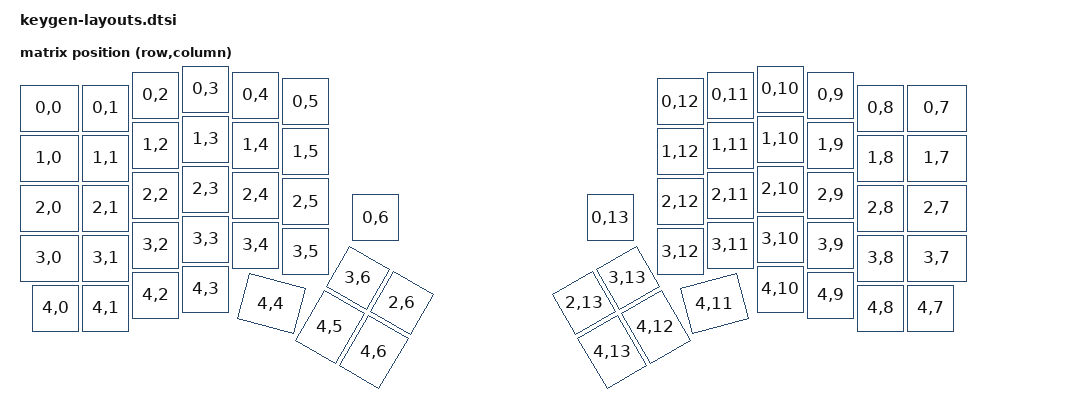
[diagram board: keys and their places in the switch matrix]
/*
 * Generated by tools/gen_zmk_layout.py from the Redox KLE in tools/gen_pcb.py - edit the script.
 * 68 key positions: 14, 12, 12, 12, 8, 4, 6 per row
 * (number row with the encoder presses, top, home, bottom, extra row, thumb top, thumb bottom).
 */

#include <dt-bindings/zmk/matrix_transform.h>
#include <physical_layouts.dtsi>

/ {
    default_transform: keymap_transform_0 {
        compatible = "zmk,matrix-transform";
        columns = <14>;
        rows = <5>;
        map = <
        RC(0,0)  RC(0,1)  RC(0,2)  RC(0,3)  RC(0,4)  RC(0,5)  RC(0,6)  RC(0,13) RC(0,12) RC(0,11) RC(0,10) RC(0,9)  RC(0,8)  RC(0,7)
        RC(1,0)  RC(1,1)  RC(1,2)  RC(1,3)  RC(1,4)  RC(1,5)  RC(1,12) RC(1,11) RC(1,10) RC(1,9)  RC(1,8)  RC(1,7)
        RC(2,0)  RC(2,1)  RC(2,2)  RC(2,3)  RC(2,4)  RC(2,5)  RC(2,12) RC(2,11) RC(2,10) RC(2,9)  RC(2,8)  RC(2,7)
        RC(3,0)  RC(3,1)  RC(3,2)  RC(3,3)  RC(3,4)  RC(3,5)  RC(3,12) RC(3,11) RC(3,10) RC(3,9)  RC(3,8)  RC(3,7)
        RC(4,0)  RC(4,1)  RC(4,2)  RC(4,3)  RC(4,10) RC(4,9)  RC(4,8)  RC(4,7)
        RC(3,6)  RC(2,6)  RC(2,13) RC(3,13)
        RC(4,4)  RC(4,5)  RC(4,6)  RC(4,13) RC(4,12) RC(4,11)
        >;
    };

    keygen_layout: keygen_layout {
        compatible = "zmk,physical-layout";
        display-name = "Keygen";
        transform = <&default_transform>;

        keys  //                        w      h      x      y    rot     rx     ry
            = <&key_physical_attrs    125    100     25     38      0      0      0>
            , <&key_physical_attrs    100    100    150     38      0      0      0>
            , <&key_physical_attrs    100    100    250     12      0      0      0>
            , <&key_physical_attrs    100    100    350      0      0      0      0>
            , <&key_physical_attrs    100    100    450     12      0      0      0>
            , <&key_physical_attrs    100    100    550     25      0      0      0>
            , <&key_physical_attrs    100    100    690    257      0      0      0>
            , <&key_physical_attrs    100    100   1160    257      0      0      0>
            , <&key_physical_attrs    100    100   1300     25      0      0      0>
            , <&key_physical_attrs    100    100   1400     12      0      0      0>
            , <&key_physical_attrs    100    100   1500      0      0      0      0>
            , <&key_physical_attrs    100    100   1600     12      0      0      0>
            , <&key_physical_attrs    100    100   1700     38      0      0      0>
            , <&key_physical_attrs    125    100   1800     38      0      0      0>
            , <&key_physical_attrs    125    100     25    138      0      0      0>
            , <&key_physical_attrs    100    100    150    138      0      0      0>
            , <&key_physical_attrs    100    100    250    112      0      0      0>
            , <&key_physical_attrs    100    100    350    100      0      0      0>
            , <&key_physical_attrs    100    100    450    112      0      0      0>
            , <&key_physical_attrs    100    100    550    125      0      0      0>
            , <&key_physical_attrs    100    100   1300    125      0      0      0>
            , <&key_physical_attrs    100    100   1400    112      0      0      0>
            , <&key_physical_attrs    100    100   1500    100      0      0      0>
            , <&key_physical_attrs    100    100   1600    112      0      0      0>
            , <&key_physical_attrs    100    100   1700    138      0      0      0>
            , <&key_physical_attrs    125    100   1800    138      0      0      0>
            , <&key_physical_attrs    125    100     25    238      0      0      0>
            , <&key_physical_attrs    100    100    150    238      0      0      0>
            , <&key_physical_attrs    100    100    250    212      0      0      0>
            , <&key_physical_attrs    100    100    350    200      0      0      0>
            , <&key_physical_attrs    100    100    450    212      0      0      0>
            , <&key_physical_attrs    100    100    550    225      0      0      0>
            , <&key_physical_attrs    100    100   1300    225      0      0      0>
            , <&key_physical_attrs    100    100   1400    212      0      0      0>
            , <&key_physical_attrs    100    100   1500    200      0      0      0>
            , <&key_physical_attrs    100    100   1600    212      0      0      0>
            , <&key_physical_attrs    100    100   1700    238      0      0      0>
            , <&key_physical_attrs    125    100   1800    238      0      0      0>
            , <&key_physical_attrs    125    100     25    338      0      0      0>
            , <&key_physical_attrs    100    100    150    338      0      0      0>
            , <&key_physical_attrs    100    100    250    312      0      0      0>
            , <&key_physical_attrs    100    100    350    300      0      0      0>
            , <&key_physical_attrs    100    100    450    312      0      0      0>
            , <&key_physical_attrs    100    100    550    325      0      0      0>
            , <&key_physical_attrs    100    100   1300    325      0      0      0>
            , <&key_physical_attrs    100    100   1400    312      0      0      0>
            , <&key_physical_attrs    100    100   1500    300      0      0      0>
            , <&key_physical_attrs    100    100   1600    312      0      0      0>
            , <&key_physical_attrs    100    100   1700    338      0      0      0>
            , <&key_physical_attrs    125    100   1800    338      0      0      0>
            , <&key_physical_attrs    100    100     50    438      0      0      0>
            , <&key_physical_attrs    100    100    150    438      0      0      0>
            , <&key_physical_attrs    100    100    250    412      0      0      0>
            , <&key_physical_attrs    100    100    350    400      0      0      0>
            , <&key_physical_attrs    100    100   1500    400      0      0      0>
            , <&key_physical_attrs    100    100   1600    412      0      0      0>
            , <&key_physical_attrs    100    100   1700    438      0      0      0>
            , <&key_physical_attrs    100    100   1800    438      0      0      0>
            , <&key_physical_attrs    100    100    650    350   3000    650    425>
            , <&key_physical_attrs    100    100    750    350   3000    650    425>
            , <&key_physical_attrs    100    100   1100    350 (-3000)   1300    425>
            , <&key_physical_attrs    100    100   1200    350 (-3000)   1300    425>
            , <&key_physical_attrs    125    100    575    275   1500      0      0>
            , <&key_physical_attrs    100    125    650    450   3000    650    425>
            , <&key_physical_attrs    100    125    750    450   3000    650    425>
            , <&key_physical_attrs    100    125   1100    450 (-3000)   1300    425>
            , <&key_physical_attrs    100    125   1200    450 (-3000)   1300    425>
            , <&key_physical_attrs    125    100   1250    275 (-1500)   1950      0>
            ;
    };
};
